# apollo510 register map
Vendor: Ambiq Micro; Series: Apollo; File version: 1.0
CPU: CM55 r1p1, little endian, MPU, FPU, double-precision FPU, DSP, I-cache, D-cache, VTOR, ITCM, DTCM, 4 interrupt priority bits, 0 interrupts, 8 SAU regions
Registers are 32-bit, read-write, reset 0x0 unless marked. A register's access mark holds for its fields unless they carry their own. Offsets are from the block's base; [hi:lo] are bit positions; {n}, {i} and the like mark numbered series.

## SECURITY — Security Interfaces
Base 0x40030000
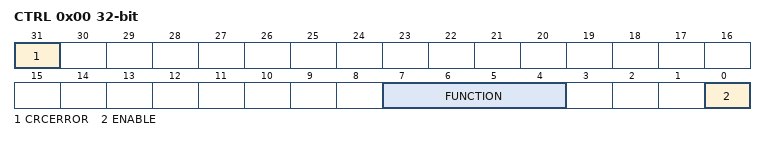
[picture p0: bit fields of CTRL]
0x00 CTRL — Control
  [31] CRCERROR — CRC Error Status - Set to 1 if an error occurs during a CRC operation. Cleared when CTRL register is written (with any value). Usually indicates an invalid address range.
  [7:4] FUNCTION — Function Select
    0=CRC32 (Perform CRC32 operation); 1=RAND (DMA pseudo-random number stream based on CRC value); 2=GENADDR (Generate DMA stream based on address)
  [0] ENABLE — Function Enable. Software should set the ENABLE bit to initiate a CRC operation. Hardware will clear the ENABLE bit upon completion.
0x10 SRCADDR — Source Addresss
  [31:0] ADDR — Source Buffer Address. Address may be byte aligned, but the length must be a multiple of 4 bits.
0x20 LEN — Length
  [23:2] LEN — Buffer size (bottom two bits assumed to be zero to ensure a multiple of 4 bytes)
0x30 RESULT — CRC Seed/Result
  [31:0] CRC — CRC Seed/Result. Software must seed the CRC with 0xFFFFFFFF before starting a CRC operation (unless the CRC is continued from a previous operation).
0x78 LOCKCTRL — LOCK Control
  [7:0] SELECT — LOCK Function Select register.
    1=LOCK01 (Enable customer OTP program.); 2=LOCK02 (Enable customer OTP read.); 17=LOCK11 (Enable Ambiq OTP program.); 18=LOCK12 (Enable Ambiq OTP read.); 157=LOCK9D (Enable Bootloader Recovery.); 158=LOCK9E (Enable Bootloader info1.); 0=RESET (Reset all.)
0x7C LOCKSTAT — LOCK Status
  [31:0] STATUS — Lock status. Bit is high to signify it is enabled. 0: LOCK01, 1: LOCK02, 4: LOCK11, 5: LOCK12, 30: LOCK9D, 31: LOCK9E
    1=LOCK01 (Enabled customer OTP program.); 2=LOCK02 (Enabled customer OTP read.); 16=LOCK11 (Enabled Ambiq OTP program.); 32=LOCK12 (Enabled Ambiq OTP read.); 0x40000000=LOCK9D (Enabled Bootloader Recovery.); 0x80000000=LOCK9E (Enabled Bootloader info1.); 0=RESET (All Reset.)
{0x80+4i} KEY{i} (i=0..3)
  [31:0] KEY{i} — Bits [{32i+31}:{32i}] of the 128-bit key should be written to this register. To protect key values, the register always returns 0x00000000.

## SSC — System security control
Base 0x40025000
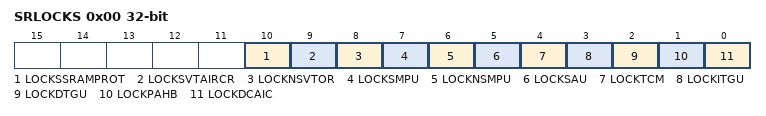
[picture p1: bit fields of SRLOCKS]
0x00 SRLOCKS — Security resource locks
  [10] LOCKSSRAMPROT — Write 1 to disables writes to the SSRAMxPROT register from software, any master, or from any debug agent. Once set, it remains locked until the next system reset. Write 0 has no effect.
  [9] LOCKSVTAIRCR — Write 1 to disable writes to the following secure registers from software or from a debug agent that is connected to the processor: VTOR_S/AIRCR.PRIS/AIRCR.BFHFNMINS. Write 0 has no effect.
  [8] LOCKNSVTOR — Write 1 to disable writes to the VTOR_NS register. Write 0 has no effect.
  [7] LOCKSMPU — Write 1 to disable writes to registers that are associated with the Secure Memory Protection Unit (MPU) region from software or from a debug agent connected to the processor. Write 0 has no effect.
  [6] LOCKNSMPU — Write 1 to disable writes to registers that are associated with the Non-secure MPU region from software or from a debug agent connected to the processor. Write 0 has no effect.
  [5] LOCKSAU — Write 1 to disable writes to registers that are associated with the SAU region from software or from a debug agent connected to the processor. Write 0 has no effect.
  [4] LOCKTCM — Write 1 to disable writes to registers that are associated with the TCM region from software or from a debug agent connected to the processor. Write 0 has no effect.
  [3] LOCKITGU — Write 1 to disable writes to registers that are associated with the ITCM interface security gating from software or from a debug agent connected to the processor. Write 0 has no effect.
  [2] LOCKDTGU — Write 1 to disable writes to registers that are associated with the DTCM interface security gating from software or from a debug agent connected to the processor. Write 0 has no effect.
  [1] LOCKPAHB — Write 1 to disable writes to the PAHBCR register from software or from a debug agent connected to the processor. Write 0 has no effect.
  [0] LOCKDCAIC — Write 1 to disable access to the instruction cache direct cache access registers DCAICLR and DCAICRR. Write 0 has no effect.
0x04 SSLOCKS — System Security locks
  [0] TCMALLSECDISABLE — Write 1 to disables TCM all secure access override. Once set, it remains locked until the next system reset. Write 0 has no effect.
